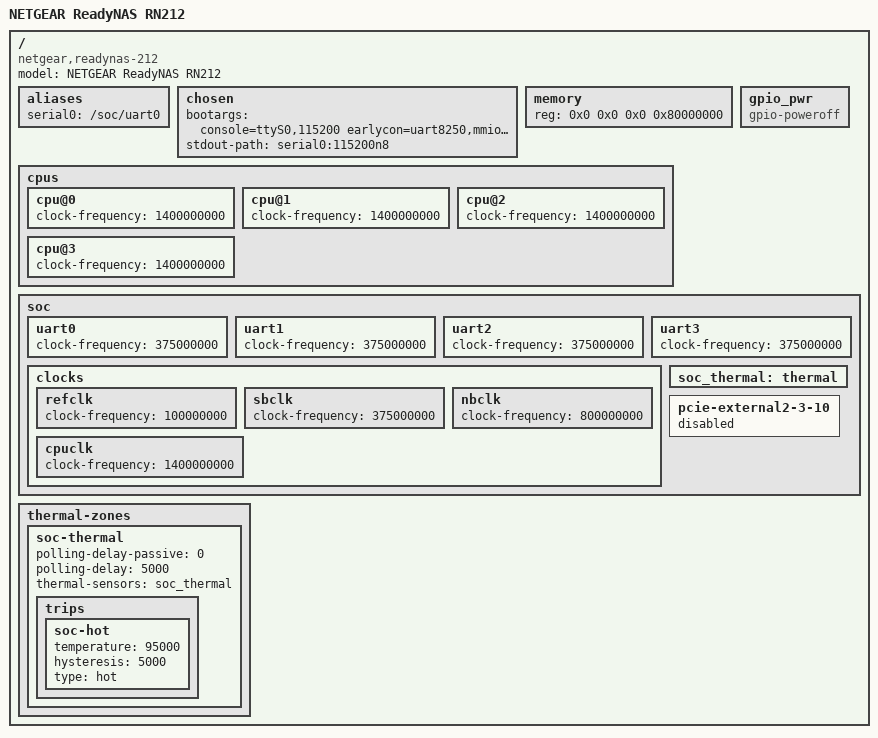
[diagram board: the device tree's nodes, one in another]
// SPDX-License-Identifier: GPL-2.0
/*
 * NETGEAR ReadyNAS RN212 (Annapurna Labs Alpine v1, 4x Cortex-A15, 2 GiB)
 *
 * Built on top of the vendor RN202 kernel DT, which the RN212's U-Boot passes
 * unchanged (bdtype=rn202). This file only fixes up what the vendor tree
 * leaves to U-Boot (memory, chosen) and drops nodes meant for the vendor
 * 3.19-era PCIe driver, which the forward-ported al-pci driver doesn't use.
 *
 * The DTB is appended to the zImage, so U-Boot's bootargs/initrd are ignored:
 * the command line below is authoritative.
 */

/dts-v1/;

/include/ "alpine-rn202-vendor.dtsi"

/ {
	model = "NETGEAR ReadyNAS RN212";
	compatible = "netgear,readynas-212", "netgear,readynas-202",
		     "annapurna-labs,alpine", "al,alpine";

	aliases {
		serial0 = "/soc/uart0";
	};

	chosen {
		bootargs = "console=ttyS0,115200 earlycon=uart8250,mmio32,0xfd883000 pci=pcie_bus_perf root=/dev/md9 rootfstype=ext4 rootwait raid=autodetect";
		stdout-path = "serial0:115200n8";
	};

	memory {
		device_type = "memory";
		reg = <0x0 0x0 0x0 0x80000000>;	/* 2 GiB */
	};

	gpio_pwr {
		compatible = "gpio-poweroff";
	};

	/*
	 * Values U-Boot patches into the vendor tree at boot (which has 0 / 1 MHz
	 * placeholders), taken from the live tree of a running RN212
	 * (/sys/firmware/devicetree, stock OS 6.10.10).
	 */
	cpus {
		cpu@0 { clock-frequency = <1400000000>; };
		cpu@1 { clock-frequency = <1400000000>; };
		cpu@2 { clock-frequency = <1400000000>; };
		cpu@3 { clock-frequency = <1400000000>; };
	};

	soc {
		uart0 { clock-frequency = <375000000>; };
		uart1 { clock-frequency = <375000000>; };
		uart2 { clock-frequency = <375000000>; };
		uart3 { clock-frequency = <375000000>; };

		clocks {
			refclk { clock-frequency = <100000000>; };
			sbclk  { clock-frequency = <375000000>; };
			nbclk  { clock-frequency = <800000000>; };
			cpuclk { clock-frequency = <1400000000>; };
		};

		/* Mainline thermal_of needs the sensor referenced from a
		 * thermal zone, or al_thermal fails to register. */
		soc_thermal: thermal { #thermal-sensor-cells = <0>; };

		/* Port 2 has nothing attached; U-Boot disables it (and never
		 * initialises the controller), so don't let al-pci probe it. */
		pcie-external2-3-10 { status = "disabled"; };

		/delete-node/ pcie-internal-3-19;
		/delete-node/ pcie-external0;
		/delete-node/ pcie-external1;
		/delete-node/ pcie-external2;
		/delete-node/ spi;		/* duplicate of spi-3-10-20 */
	};

	/*
	 * SoC temperature only; the fan (G762) has no cooling-device support,
	 * so fan control stays in userspace. "hot" just logs: no critical trip
	 * until the sensor's readings are known to be sane.
	 */
	thermal-zones {
		soc-thermal {
			polling-delay-passive = <0>;
			polling-delay = <5000>;
			thermal-sensors = <&soc_thermal>;

			trips {
				soc-hot {
					temperature = <95000>;
					hysteresis = <5000>;
					type = "hot";
				};
			};
		};
	};
};
